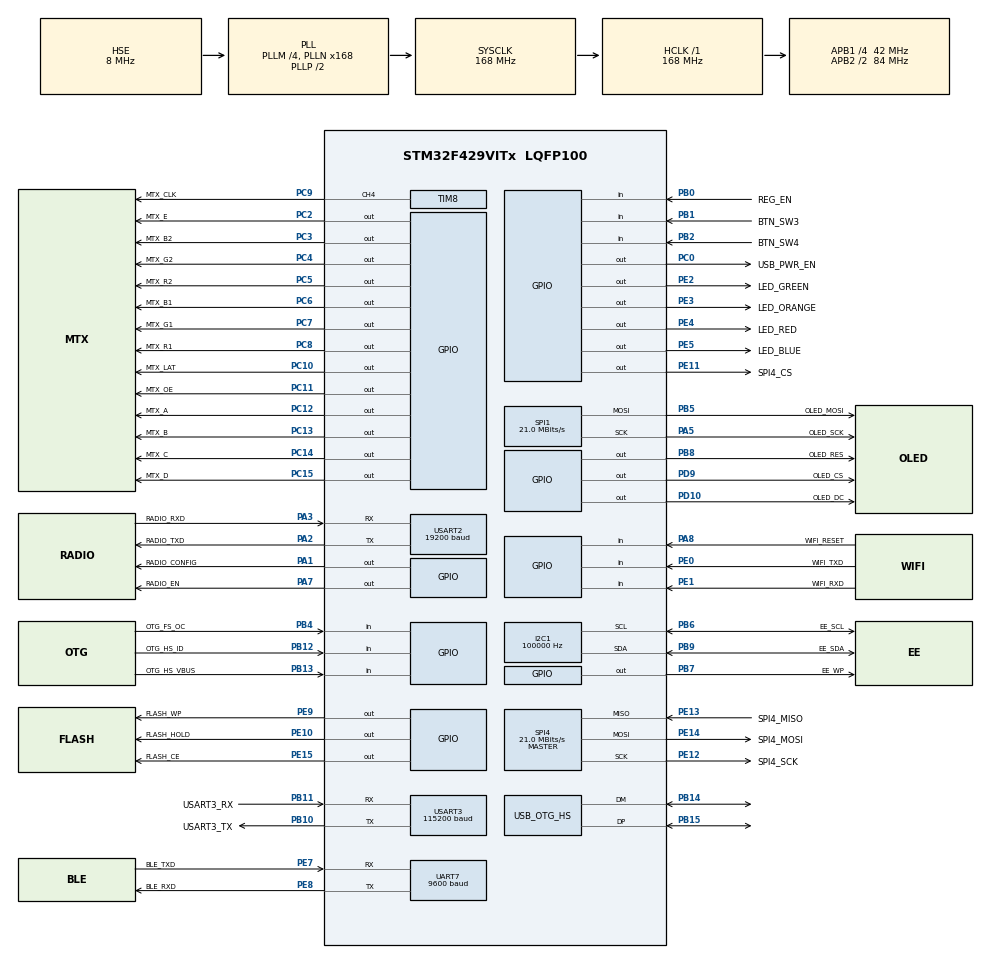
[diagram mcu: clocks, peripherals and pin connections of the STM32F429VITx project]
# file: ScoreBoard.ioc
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Dma.Request0=TIM8_UP
Dma.Request1=TIM8_CH1
Dma.TIM8_CH1.1.Direction=DMA_MEMORY_TO_PERIPH
Dma.TIM8_CH1.1.FIFOMode=DMA_FIFOMODE_ENABLE
Dma.TIM8_CH1.1.FIFOThreshold=DMA_FIFO_THRESHOLD_3QUARTERSFULL
Dma.TIM8_CH1.1.Instance=DMA2_Stream2
Dma.TIM8_CH1.1.MemBurst=DMA_MBURST_SINGLE
Dma.TIM8_CH1.1.MemDataAlignment=DMA_MDATAALIGN_HALFWORD
Dma.TIM8_CH1.1.MemInc=DMA_MINC_ENABLE
Dma.TIM8_CH1.1.Mode=DMA_CIRCULAR
Dma.TIM8_CH1.1.PeriphBurst=DMA_PBURST_SINGLE
Dma.TIM8_CH1.1.PeriphDataAlignment=DMA_PDATAALIGN_HALFWORD
Dma.TIM8_CH1.1.PeriphInc=DMA_PINC_DISABLE
Dma.TIM8_CH1.1.Priority=DMA_PRIORITY_HIGH
Dma.TIM8_UP.0.Direction=DMA_MEMORY_TO_PERIPH
Dma.TIM8_UP.0.FIFOMode=DMA_FIFOMODE_ENABLE
Dma.TIM8_UP.0.FIFOThreshold=DMA_FIFO_THRESHOLD_3QUARTERSFULL
Dma.TIM8_UP.0.Instance=DMA2_Stream1
Dma.TIM8_UP.0.MemBurst=DMA_MBURST_SINGLE
Dma.TIM8_UP.0.MemDataAlignment=DMA_MDATAALIGN_HALFWORD
Dma.TIM8_UP.0.MemInc=DMA_MINC_ENABLE
Dma.TIM8_UP.0.Mode=DMA_CIRCULAR
Dma.TIM8_UP.0.PeriphBurst=DMA_PBURST_SINGLE
Dma.TIM8_UP.0.PeriphDataAlignment=DMA_PDATAALIGN_HALFWORD
Dma.TIM8_UP.0.PeriphInc=DMA_PINC_DISABLE
Dma.TIM8_UP.0.Priority=DMA_PRIORITY_VERY_HIGH
FREERTOS.Tasks01=defaultTask,24,2048,StartDefaultTask,Default,NULL,Dynamic,NULL,NULL
FREERTOS.configTOTAL_HEAP_SIZE=40000
FREERTOS.configUSE_NEWLIB_REENTRANT=1
I2C1.ClockSpeed=100000
Mcu.Family=STM32F4
Mcu.Name=STM32F429VITx
Mcu.Package=LQFP100
NVIC.DMA2_Stream1_IRQn=true\:5\:0\:false\:false\:true\:false\:false\:true\:true
NVIC.DMA2_Stream2_IRQn=true\:5\:0\:false\:false\:true\:true\:false\:true\:true
NVIC.OTG_HS_IRQn=true\:5\:0\:false\:false\:true\:true\:false\:true\:true
NVIC.PriorityGroup=NVIC_PRIORITYGROUP_4
NVIC.RCC_IRQn=true\:5\:0\:false\:false\:true\:true\:true\:false\:true
NVIC.TIM6_DAC_IRQn=true\:15\:0\:false\:false\:true\:false\:false\:true\:true
NVIC.TimeBase=TIM6_DAC_IRQn
NVIC.TimeBaseIP=TIM6
NVIC.UART7_IRQn=true\:5\:0\:false\:false\:true\:true\:true\:true\:true
NVIC.USART2_IRQn=true\:5\:0\:false\:false\:true\:true\:true\:true\:true
NVIC.USART3_IRQn=true\:5\:0\:false\:false\:true\:true\:true\:true\:true
PA1.GPIO_Label=RADIO_CONFIG
PA1.PinState=GPIO_PIN_SET
PA1.Signal=GPIO_Output
PA13.Mode=Serial_Wire
PA13.Signal=SYS_JTMS-SWDIO
PA14.Mode=Serial_Wire
PA14.Signal=SYS_JTCK-SWCLK
PA2.GPIO_Label=RADIO_TXD
PA2.Mode=Asynchronous
PA2.Signal=USART2_TX
PA3.GPIO_Label=RADIO_RXD
PA3.Mode=Asynchronous
PA3.Signal=USART2_RX
PA5.GPIO_Label=OLED_SCK
PA5.Mode=TX_Only_Simplex_Unidirect_Master
PA5.Signal=SPI1_SCK
PA7.GPIO_Label=RADIO_EN
PA7.Signal=GPIO_Output
PA8.GPIO_Label=WIFI_RESET
PA8.Signal=GPIO_Input
PB0.GPIO_Label=REG_EN
PB0.Signal=GPIO_Input
PB1.GPIO_Label=BTN_SW3
PB1.Signal=GPIO_Input
PB10.GPIO_Label=USART3_TX
PB10.Mode=Asynchronous
PB10.Signal=USART3_TX
PB11.GPIO_Label=USART3_RX
PB11.Mode=Asynchronous
PB11.Signal=USART3_RX
PB12.GPIO_Label=OTG_HS_ID
PB12.Signal=GPIO_Input
PB13.GPIO_Label=OTG_HS_VBUS
PB13.Signal=GPIO_Input
PB14.Mode=Host_FS
PB14.Signal=USB_OTG_HS_DM
PB15.Mode=Host_FS
PB15.Signal=USB_OTG_HS_DP
PB2/BOOT1.GPIO_Label=BTN_SW4
PB2/BOOT1.Signal=GPIO_Input
PB4.GPIO_Label=OTG_FS_OC
PB4.Signal=GPIO_Input
PB5.GPIO_Label=OLED_MOSI
PB5.Mode=TX_Only_Simplex_Unidirect_Master
PB5.Signal=SPI1_MOSI
PB6.GPIO_Label=EE_SCL
PB6.GPIO_Pu=GPIO_PULLUP
PB6.Mode=I2C
PB6.Signal=I2C1_SCL
PB7.GPIO_Label=EE_WP
PB7.Signal=GPIO_Output
PB8.GPIO_Label=OLED_RES
PB8.Signal=GPIO_Output
PB9.GPIO_Label=EE_SDA
PB9.GPIO_Pu=GPIO_PULLUP
PB9.Mode=I2C
PB9.Signal=I2C1_SDA
PC0.GPIO_Label=USB_PWR_EN
PC0.PinState=GPIO_PIN_SET
PC0.Signal=GPIO_Output
PC10.GPIO_Label=MTX_LAT
PC10.GPIO_PuPd=GPIO_PULLUP
PC10.GPIO_Speed=GPIO_SPEED_FREQ_VERY_HIGH
PC10.Signal=GPIO_Output
PC11.GPIO_Label=MTX_OE
PC11.GPIO_PuPd=GPIO_PULLUP
PC11.GPIO_Speed=GPIO_SPEED_FREQ_VERY_HIGH
PC11.Signal=GPIO_Output
PC12.GPIO_Label=MTX_A
PC12.GPIO_PuPd=GPIO_PULLUP
PC12.GPIO_Speed=GPIO_SPEED_FREQ_VERY_HIGH
PC12.Signal=GPIO_Output
PC13.GPIO_Label=MTX_B
PC13.GPIO_PuPd=GPIO_PULLUP
PC13.GPIO_Speed=GPIO_SPEED_FREQ_VERY_HIGH
PC13.Signal=GPIO_Output
PC14/OSC32_IN.GPIO_Label=MTX_C
PC14/OSC32_IN.GPIO_PuPd=GPIO_PULLUP
PC14/OSC32_IN.GPIO_Speed=GPIO_SPEED_FREQ_VERY_HIGH
PC14/OSC32_IN.Signal=GPIO_Output
PC15/OSC32_OUT.GPIO_Label=MTX_D
PC15/OSC32_OUT.GPIO_PuPd=GPIO_PULLUP
PC15/OSC32_OUT.GPIO_Speed=GPIO_SPEED_FREQ_VERY_HIGH
PC15/OSC32_OUT.Signal=GPIO_Output
PC2.GPIO_Label=MTX_E
PC2.GPIO_PuPd=GPIO_PULLUP
PC2.GPIO_Speed=GPIO_SPEED_FREQ_VERY_HIGH
PC2.Signal=GPIO_Output
PC3.GPIO_Label=MTX_B2
PC3.GPIO_PuPd=GPIO_PULLUP
PC3.GPIO_Speed=GPIO_SPEED_FREQ_VERY_HIGH
PC3.Signal=GPIO_Output
PC4.GPIO_Label=MTX_G2
PC4.GPIO_PuPd=GPIO_PULLUP
PC4.GPIO_Speed=GPIO_SPEED_FREQ_VERY_HIGH
PC4.Signal=GPIO_Output
PC5.GPIO_Label=MTX_R2
PC5.GPIO_PuPd=GPIO_PULLUP
PC5.GPIO_Speed=GPIO_SPEED_FREQ_VERY_HIGH
PC5.Signal=GPIO_Output
PC6.GPIO_Label=MTX_B1
PC6.GPIO_PuPd=GPIO_PULLUP
PC6.GPIO_Speed=GPIO_SPEED_FREQ_VERY_HIGH
PC6.Signal=GPIO_Output
PC7.GPIO_Label=MTX_G1
PC7.GPIO_PuPd=GPIO_PULLUP
PC7.GPIO_Speed=GPIO_SPEED_FREQ_VERY_HIGH
PC7.Signal=GPIO_Output
PC8.GPIO_Label=MTX_R1
PC8.GPIO_PuPd=GPIO_PULLUP
PC8.GPIO_Speed=GPIO_SPEED_FREQ_VERY_HIGH
PC8.Signal=GPIO_Output
PC9.GPIO_Label=MTX_CLK
PC9.Signal=S_TIM8_CH4
PD10.GPIO_Label=OLED_DC
PD10.Signal=GPIO_Output
PD9.GPIO_Label=OLED_CS
PD9.PinState=GPIO_PIN_SET
PD9.Signal=GPIO_Output
PE0.GPIO_Label=WIFI_TXD
PE0.Signal=GPIO_Input
PE1.GPIO_Label=WIFI_RXD
PE1.Signal=GPIO_Input
PE10.GPIO_Label=FLASH_HOLD
PE10.PinState=GPIO_PIN_SET
PE10.Signal=GPIO_Output
PE11.GPIO_Label=SPI4_CS
PE11.PinState=GPIO_PIN_SET
PE11.Signal=GPIO_Output
PE12.GPIO_Label=SPI4_SCK
PE12.Mode=Full_Duplex_Master
PE12.Signal=SPI4_SCK
PE13.GPIO_Label=SPI4_MISO
PE13.Mode=Full_Duplex_Master
PE13.Signal=SPI4_MISO
PE14.GPIO_Label=SPI4_MOSI
PE14.Mode=Full_Duplex_Master
PE14.Signal=SPI4_MOSI
PE15.GPIO_Label=FLASH_CE
PE15.PinState=GPIO_PIN_SET
PE15.Signal=GPIO_Output
PE2.GPIO_Label=LED_GREEN
PE2.Signal=GPIO_Output
PE3.GPIO_Label=LED_ORANGE
PE3.Signal=GPIO_Output
PE4.GPIO_Label=LED_RED
PE4.Signal=GPIO_Output
PE5.GPIO_Label=LED_BLUE
PE5.Signal=GPIO_Output
PE7.GPIO_Label=BLE_TXD
PE7.Mode=Asynchronous
PE7.Signal=UART7_RX
PE8.GPIO_Label=BLE_RXD
PE8.Mode=Asynchronous
PE8.Signal=UART7_TX
PE9.GPIO_Label=FLASH_WP
PE9.PinState=GPIO_PIN_SET
PE9.Signal=GPIO_Output
PH0/OSC_IN.Mode=HSE-External-Oscillator
PH0/OSC_IN.Signal=RCC_OSC_IN
PH1/OSC_OUT.Mode=HSE-External-Oscillator
PH1/OSC_OUT.Signal=RCC_OSC_OUT
ProjectManager.HeapSize=0x200
ProjectManager.StackSize=0x400
ProjectManager.TargetToolchain=CMake
RCC.48MHZClocksFreq_Value=48000000
RCC.AHBFreq_Value=168000000
RCC.APB1CLKDivider=RCC_HCLK_DIV4
RCC.APB1Freq_Value=42000000
RCC.APB1TimFreq_Value=84000000
RCC.APB2CLKDivider=RCC_HCLK_DIV2
RCC.APB2Freq_Value=84000000
RCC.APB2TimFreq_Value=168000000
RCC.CortexFreq_Value=168000000
RCC.EnbaleCSS=true
RCC.HCLKFreq_Value=168000000
RCC.HSE_VALUE=8000000
RCC.HSI_VALUE=16000000
RCC.LSE_VALUE=32768
RCC.PLLM=4
RCC.PLLN=168
RCC.PLLQ=7
RCC.RTCClockSelection=RCC_RTCCLKSOURCE_LSI
RCC.SYSCLKFreq_VALUE=168000000
RCC.SYSCLKSource=RCC_SYSCLKSOURCE_PLLCLK
RCC.VCOOutputFreq_Value=336000000
RTC.Format=RTC_FORMAT_BIN
SH.S_TIM8_CH4.0=TIM8_CH4,PWM Generation4 CH4
SPI1.BaudRatePrescaler=SPI_BAUDRATEPRESCALER_4
SPI1.CLKPhase=SPI_PHASE_2EDGE
SPI1.CLKPolarity=SPI_POLARITY_HIGH
SPI1.CalculateBaudRate=21.0 MBits/s
SPI1.DataSize=SPI_DATASIZE_8BIT
SPI1.Direction=SPI_DIRECTION_2LINES
SPI1.Mode=SPI_MODE_MASTER
SPI1.VirtualType=VM_MASTER
SPI4.BaudRatePrescaler=SPI_BAUDRATEPRESCALER_4
SPI4.CLKPhase=SPI_PHASE_1EDGE
SPI4.CLKPolarity=SPI_POLARITY_LOW
SPI4.CalculateBaudRate=21.0 MBits/s
SPI4.DataSize=SPI_DATASIZE_8BIT
SPI4.Direction=SPI_DIRECTION_2LINES
SPI4.Mode=SPI_MODE_MASTER
SPI4.VirtualType=VM_MASTER
TIM8.AutoReloadPreload=TIM_AUTORELOAD_PRELOAD_ENABLE
TIM8.Channel-Output\ Compare1\ No\ Output=TIM_CHANNEL_1
TIM8.Channel-PWM\ Generation4\ CH4=TIM_CHANNEL_4
TIM8.OCPolarity_4=TIM_OCPOLARITY_LOW
TIM8.Period=9
TIM8.Prescaler=0
TIM8.Pulse-PWM\ Generation4\ CH4=5
UART7.BaudRate=9600
UART7.VirtualMode=Asynchronous
USART2.BaudRate=19200
USART2.VirtualMode=VM_ASYNC
USART3.BaudRate=115200
USART3.VirtualMode=VM_ASYNC
USB_HOST.BSP.number=1
USB_HOST.USBH_HandleTypeDef-HID_HS=hUsbHostHS
USB_HOST.USBH_PROCESS_STACK_SIZE=2048
USB_HOST.VirtualModeHS=Hid
USB_HOST0.BSP.STBoard=false
USB_HOST0.BSP.api=Unknown
USB_HOST0.BSP.instance=PC0
USB_HOST0.BSP.ip=GPIO
USB_HOST0.BSP.mode=Output
USB_HOST0.BSP.name=Drive_VBUS_HS
USB_HOST0.BSP.solution=PC0
USB_OTG_HS.VirtualMode-Host_FS=Host_FS
VP_FREERTOS_VS_CMSIS_V2.Mode=CMSIS_V2
VP_RNG_VS_RNG.Mode=RNG_Activate
VP_RTC_VS_RTC_Activate.Mode=RTC_Enabled
VP_SYS_VS_tim6.Mode=TIM6
VP_TIM8_VS_ClockSourceINT.Mode=Internal
VP_TIM8_VS_no_output1.Mode=Output Compare1 No Output
VP_USB_HOST_VS_USB_HOST_HID_HS.Mode=HID_HS
board=custom

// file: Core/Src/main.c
/* USER CODE BEGIN Header */
/**
  ******************************************************************************
  * @file           : main.c
  * @brief          : Main program body
  ******************************************************************************
  * @attention
  *
  * Copyright (c) 2026 STMicroelectronics.
  * All rights reserved.
  *
  * This software is licensed under terms that can be found in the LICENSE file
  * in the root directory of this software component.
  * If no LICENSE file comes with this software, it is provided AS-IS.
  *
  ******************************************************************************
  */
/* USER CODE END Header */
#include "main.h"
#include "cmsis_os.h"
#include "dma.h"
#include "i2c.h"
#include "rng.h"
#include "rtc.h"
#include "spi.h"
#include "tim.h"
#include "usart.h"
#include "usb_host.h"
#include "gpio.h"

/* USER CODE BEGIN Includes */
#include "app_hal.h"

/* USER CODE END Includes */

void SystemClock_Config(void);
void MX_FREERTOS_Init(void);

int main(void)
{

  /* MCU Configuration--------------------------------------------------------*/

  /* Reset of all peripherals, Initializes the Flash interface and the Systick. */
  HAL_Init();

  /* Configure the system clock */
  SystemClock_Config();

  /* Initialize all configured peripherals */
  MX_GPIO_Init();
  MX_DMA_Init();
  MX_USART3_UART_Init();
  MX_USART2_UART_Init();
  MX_SPI1_Init();
  MX_I2C1_Init();
  MX_RTC_Init();
  MX_RNG_Init();
  MX_TIM8_Init();
  MX_UART7_Init();
  MX_SPI4_Init();

  /* Init scheduler */
  osKernelInitialize();  /* Call init function for freertos objects (in cmsis_os2.c) */
  MX_FREERTOS_Init();

  /* Start scheduler */
  osKernelStart();

  /* We should never get here as control is now taken by the scheduler */

  /* Infinite loop */
  while (1)
  {

  }
}

void SystemClock_Config(void)
{
  RCC_OscInitTypeDef RCC_OscInitStruct = {0};
  RCC_ClkInitTypeDef RCC_ClkInitStruct = {0};

  /** Configure the main internal regulator output voltage
  */
  __HAL_RCC_PWR_CLK_ENABLE();
  __HAL_PWR_VOLTAGESCALING_CONFIG(PWR_REGULATOR_VOLTAGE_SCALE1);

  /** Initializes the RCC Oscillators according to the specified parameters
  * in the RCC_OscInitTypeDef structure.
  */
  RCC_OscInitStruct.OscillatorType = RCC_OSCILLATORTYPE_LSI|RCC_OSCILLATORTYPE_HSE;
  RCC_OscInitStruct.HSEState = RCC_HSE_ON;
  RCC_OscInitStruct.LSIState = RCC_LSI_ON;
  RCC_OscInitStruct.PLL.PLLState = RCC_PLL_ON;
  RCC_OscInitStruct.PLL.PLLSource = RCC_PLLSOURCE_HSE;
  RCC_OscInitStruct.PLL.PLLM = 4;
  RCC_OscInitStruct.PLL.PLLN = 168;
  RCC_OscInitStruct.PLL.PLLP = RCC_PLLP_DIV2;
  RCC_OscInitStruct.PLL.PLLQ = 7;
  if (HAL_RCC_OscConfig(&RCC_OscInitStruct) != HAL_OK)
  {
    Error_Handler();
  }

  /** Initializes the CPU, AHB and APB buses clocks
  */
  RCC_ClkInitStruct.ClockType = RCC_CLOCKTYPE_HCLK|RCC_CLOCKTYPE_SYSCLK
                              |RCC_CLOCKTYPE_PCLK1|RCC_CLOCKTYPE_PCLK2;
  RCC_ClkInitStruct.SYSCLKSource = RCC_SYSCLKSOURCE_PLLCLK;
  RCC_ClkInitStruct.AHBCLKDivider = RCC_SYSCLK_DIV1;
  RCC_ClkInitStruct.APB1CLKDivider = RCC_HCLK_DIV4;
  RCC_ClkInitStruct.APB2CLKDivider = RCC_HCLK_DIV2;

  if (HAL_RCC_ClockConfig(&RCC_ClkInitStruct, FLASH_LATENCY_5) != HAL_OK)
  {
    Error_Handler();
  }

  /** Enables the Clock Security System
  */
  HAL_RCC_EnableCSS();
}

void HAL_TIM_PeriodElapsedCallback(TIM_HandleTypeDef *htim)
{
  if (htim->Instance == TIM6)
  {
    HAL_IncTick();
  }
}

void Error_Handler(void)
{
  __disable_irq();
  while (1)
  {
  }
}

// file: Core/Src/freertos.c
/* USER CODE BEGIN Header */
/**
  ******************************************************************************
  * File Name          : freertos.c
  * Description        : Code for freertos applications
  ******************************************************************************
  * @attention
  *
  * Copyright (c) 2026 STMicroelectronics.
  * All rights reserved.
  *
  * This software is licensed under terms that can be found in the LICENSE file
  * in the root directory of this software component.
  * If no LICENSE file comes with this software, it is provided AS-IS.
  *
  ******************************************************************************
  */
/* USER CODE END Header */

#include "FreeRTOS.h"
#include "task.h"
#include "main.h"
#include "cmsis_os.h"

/* USER CODE BEGIN Includes */
#include "app_hal.h"

/* USER CODE END Includes */

/* Definitions for defaultTask */
osThreadId_t defaultTaskHandle;
const osThreadAttr_t defaultTask_attributes = {
  .name = "defaultTask",
  .stack_size = 2048 * 4,
  .priority = (osPriority_t) osPriorityNormal,
};

void StartDefaultTask(void *argument);

extern void MX_USB_HOST_Init(void);
void MX_FREERTOS_Init(void); /* (MISRA C 2004 rule 8.1) */

void MX_FREERTOS_Init(void) {

  /* Create the thread(s) */
  /* creation of defaultTask */
  defaultTaskHandle = osThreadNew(StartDefaultTask, NULL, &defaultTask_attributes);

}

void StartDefaultTask(void *argument)
{
  /* init code for USB_HOST */
  MX_USB_HOST_Init();
  /* USER CODE BEGIN StartDefaultTask */
  App_Init();   /* original scoreboard start-up (App/Main/app_main.c) */
  App_Run();    /* App task loop: serial commands + game/display jobs, never returns */
  /* Infinite loop */
  for(;;)
  {
    osDelay(1);
  }
  /* USER CODE END StartDefaultTask */
}
